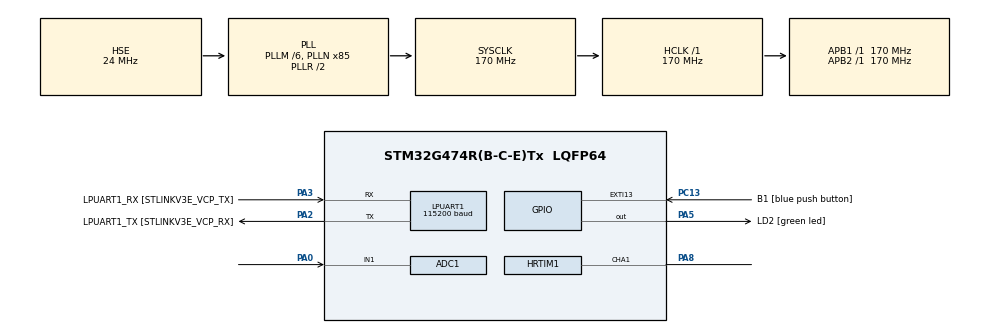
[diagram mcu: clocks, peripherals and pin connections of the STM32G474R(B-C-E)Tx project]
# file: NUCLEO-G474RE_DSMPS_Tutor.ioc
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ADC1.Channel-0\#ChannelRegularConversion=ADC_CHANNEL_1
ADC1.ClockPrescaler=ADC_CLOCK_SYNC_PCLK_DIV4
ADC1.EnableInjectedConversion=ENABLE
ADC1.ExternalTrigInjecConv=ADC_EXTERNALTRIGINJEC_HRTIM_TRG2
ADC1.InjNumberOfConversion=1
ADC1.InjectedChannel-1\#ChannelInjectedConversion=ADC_CHANNEL_1
ADC1.InjectedOffsetNumber-1\#ChannelInjectedConversion=ADC_OFFSET_NONE
ADC1.InjectedRank-1\#ChannelInjectedConversion=1
ADC1.InjectedSamplingTime-1\#ChannelInjectedConversion=ADC_SAMPLETIME_2CYCLES_5
ADC1.NbrOfConversionFlag=1
ADC1.OffsetNumber-0\#ChannelRegularConversion=ADC_OFFSET_NONE
ADC1.Rank-0\#ChannelRegularConversion=1
ADC1.Rank1_Channel=ADC_CHANNEL_1
ADC1.SamplingTime-0\#ChannelRegularConversion=ADC_SAMPLETIME_2CYCLES_5
ADC1.master=1
HRTIM1.ADCTrigger2_Source1=HRTIM_ADCTRIGGEREVENT24_TIMERA_PERIOD
HRTIM1.ADCTrigger_Id2=HRTIM_ADCTRIGGER_2
HRTIM1.CompareUnit1-Output_TA1=HRTIM_COMPAREUNIT_1
HRTIM1.CompareValue1-Output_TA1=54400/2
HRTIM1.NumberADCTriggerSource2=1
HRTIM1.NumberResetSource1-Output_TA1=1
HRTIM1.NumberSetSource1-Output_TA1=1
HRTIM1.NumberUpdateTrigger-Output_TA1=0
HRTIM1.Periode_TA=54400
HRTIM1.ResetOutput1_Source1-Output_TA1=HRTIM_OUTPUTRESET_TIMCMP1
HRTIM1.SetOutput1_Source1-Output_TA1=HRTIM_OUTPUTSET_TIMPER
LPUART1.BaudRate=115200
LPUART1.WordLength=UART_WORDLENGTH_8B
Mcu.Family=STM32G4
Mcu.Name=STM32G474R(B-C-E)Tx
Mcu.Package=LQFP64
NVIC.ADC1_2_IRQn=true\:0\:0\:false\:false\:true\:true\:true\:true
NVIC.EXTI15_10_IRQn=true\:0\:0\:false\:false\:true\:true\:true\:true
NVIC.PriorityGroup=NVIC_PRIORITYGROUP_4
PA0.Mode=IN1-Single-Ended
PA0.Signal=ADC1_IN1
PA13.GPIO_Label=T_SWDIO
PA13.Mode=Trace_Asynchronous_SW
PA13.Signal=SYS_JTMS-SWDIO
PA14.GPIO_Label=T_SWCLK
PA14.Mode=Trace_Asynchronous_SW
PA14.Signal=SYS_JTCK-SWCLK
PA2.GPIO_Label=LPUART1_TX [STLINKV3E_VCP_RX]
PA2.Mode=Asynchronous
PA2.Signal=LPUART1_TX
PA3.GPIO_Label=LPUART1_RX [STLINKV3E_VCP_TX]
PA3.Mode=Asynchronous
PA3.Signal=LPUART1_RX
PA5.GPIO_Label=LD2 [green led]
PA5.Signal=GPIO_Output
PA8.GPIO_Speed_High_Default=GPIO_SPEED_FREQ_LOW
PA8.Mode=Output_TA1
PA8.Signal=HRTIM1_CHA1
PB3.GPIO_Label=T_SWO
PB3.Mode=Trace_Asynchronous_SW
PB3.Signal=SYS_JTDO-SWO
PC13.GPIO_Label=B1 [blue push button]
PC13.Signal=GPXTI13
PC14-OSC32_IN.Mode=LSE-External-Oscillator
PC14-OSC32_IN.Signal=RCC_OSC32_IN
PC15-OSC32_OUT.Mode=LSE-External-Oscillator
PC15-OSC32_OUT.Signal=RCC_OSC32_OUT
PF0-OSC_IN.Mode=HSE-External-Oscillator
PF0-OSC_IN.Signal=RCC_OSC_IN
PF1-OSC_OUT.Mode=HSE-External-Oscillator
PF1-OSC_OUT.Signal=RCC_OSC_OUT
ProjectManager.HeapSize=0x200
ProjectManager.StackSize=0x400
ProjectManager.TargetToolchain=STM32CubeIDE
RCC.ADC12Freq_Value=170000000
RCC.ADC345Freq_Value=170000000
RCC.AHBFreq_Value=170000000
RCC.APB1Freq_Value=170000000
RCC.APB1TimFreq_Value=170000000
RCC.APB2Freq_Value=170000000
RCC.APB2TimFreq_Value=170000000
RCC.CortexFreq_Value=170000000
RCC.EXTERNAL_CLOCK_VALUE=12288000
RCC.HCLKFreq_Value=170000000
RCC.HSE_VALUE=24000000
RCC.HSI48_VALUE=48000000
RCC.HSI_VALUE=16000000
RCC.PLLM=RCC_PLLM_DIV6
RCC.PLLN=85
RCC.PLLSourceVirtual=RCC_PLLSOURCE_HSE
RCC.RTCClockSelection=RCC_RTCCLKSOURCE_LSE
RCC.SYSCLKFreq_VALUE=170000000
RCC.SYSCLKSource=RCC_SYSCLKSOURCE_PLLCLK
RCC.USBFreq_Value=170000000
RCC.VCOOutputFreq_Value=340000000
VP_SYS_VS_DBSignals.Mode=DisableDeadBatterySignals
board=NUCLEO-G474RE

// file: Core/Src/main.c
/* USER CODE BEGIN Header */
/**
  ******************************************************************************
  * @file           : main.c
  * @brief          : Main program body
  ******************************************************************************
  * @attention
  *
  * Copyright (c) 2023 STMicroelectronics.
  * All rights reserved.
  *
  * This software is licensed under terms that can be found in the LICENSE file
  * in the root directory of this software component.
  * If no LICENSE file comes with this software, it is provided AS-IS.
  *
  ******************************************************************************
  */
/* USER CODE END Header */
#include "main.h"

ADC_HandleTypeDef hadc1;

HRTIM_HandleTypeDef hhrtim1;

UART_HandleTypeDef hlpuart1;

/* USER CODE BEGIN PV */

uint16_t VoutMeasured;

/* USER CODE END PV */

void SystemClock_Config(void);
static void MX_GPIO_Init(void);
static void MX_LPUART1_UART_Init(void);
static void MX_ADC1_Init(void);
static void MX_HRTIM1_Init(void);

int main(void)
{

  /* MCU Configuration--------------------------------------------------------*/

  /* Reset of all peripherals, Initializes the Flash interface and the Systick. */
  HAL_Init();

  /* Configure the system clock */
  SystemClock_Config();

  /* Initialize all configured peripherals */
  MX_GPIO_Init();
  MX_LPUART1_UART_Init();
  MX_ADC1_Init();
  MX_HRTIM1_Init();
  /* USER CODE BEGIN 2 */

  HAL_HRTIM_WaveformOutputStart(&hhrtim1, HRTIM_OUTPUT_TA1);
  HAL_HRTIM_WaveformCounterStart(&hhrtim1, HRTIM_TIMERID_TIMER_A);

  /* Run the ADC calibration in single-ended mode */
  HAL_ADCEx_Calibration_Start(&hadc1, ADC_SINGLE_ENDED);

  /* Start ADC1 Injected Conversions with Interrupt*/
  HAL_ADCEx_InjectedStart_IT(&hadc1);

  /* USER CODE END 2 */

  /* Infinite loop */
  while (1)
  {

  }
}

void SystemClock_Config(void)
{
  RCC_OscInitTypeDef RCC_OscInitStruct = {0};
  RCC_ClkInitTypeDef RCC_ClkInitStruct = {0};

  /** Configure the main internal regulator output voltage
  */
  HAL_PWREx_ControlVoltageScaling(PWR_REGULATOR_VOLTAGE_SCALE1_BOOST);

  /** Initializes the RCC Oscillators according to the specified parameters
  * in the RCC_OscInitTypeDef structure.
  */
  RCC_OscInitStruct.OscillatorType = RCC_OSCILLATORTYPE_HSE;
  RCC_OscInitStruct.HSEState = RCC_HSE_ON;
  RCC_OscInitStruct.PLL.PLLState = RCC_PLL_ON;
  RCC_OscInitStruct.PLL.PLLSource = RCC_PLLSOURCE_HSE;
  RCC_OscInitStruct.PLL.PLLM = RCC_PLLM_DIV6;
  RCC_OscInitStruct.PLL.PLLN = 85;
  RCC_OscInitStruct.PLL.PLLP = RCC_PLLP_DIV2;
  RCC_OscInitStruct.PLL.PLLQ = RCC_PLLQ_DIV2;
  RCC_OscInitStruct.PLL.PLLR = RCC_PLLR_DIV2;
  if (HAL_RCC_OscConfig(&RCC_OscInitStruct) != HAL_OK)
  {
    Error_Handler();
  }

  /** Initializes the CPU, AHB and APB buses clocks
  */
  RCC_ClkInitStruct.ClockType = RCC_CLOCKTYPE_HCLK|RCC_CLOCKTYPE_SYSCLK
                              |RCC_CLOCKTYPE_PCLK1|RCC_CLOCKTYPE_PCLK2;
  RCC_ClkInitStruct.SYSCLKSource = RCC_SYSCLKSOURCE_PLLCLK;
  RCC_ClkInitStruct.AHBCLKDivider = RCC_SYSCLK_DIV1;
  RCC_ClkInitStruct.APB1CLKDivider = RCC_HCLK_DIV1;
  RCC_ClkInitStruct.APB2CLKDivider = RCC_HCLK_DIV1;

  if (HAL_RCC_ClockConfig(&RCC_ClkInitStruct, FLASH_LATENCY_4) != HAL_OK)
  {
    Error_Handler();
  }
}

static void MX_ADC1_Init(void)
{

  ADC_MultiModeTypeDef multimode = {0};
  ADC_ChannelConfTypeDef sConfig = {0};
  ADC_InjectionConfTypeDef sConfigInjected = {0};

  /** Common config
  */
  hadc1.Instance = ADC1;
  hadc1.Init.ClockPrescaler = ADC_CLOCK_SYNC_PCLK_DIV4;
  hadc1.Init.Resolution = ADC_RESOLUTION_12B;
  hadc1.Init.DataAlign = ADC_DATAALIGN_RIGHT;
  hadc1.Init.GainCompensation = 0;
  hadc1.Init.ScanConvMode = ADC_SCAN_DISABLE;
  hadc1.Init.EOCSelection = ADC_EOC_SINGLE_CONV;
  hadc1.Init.LowPowerAutoWait = DISABLE;
  hadc1.Init.ContinuousConvMode = DISABLE;
  hadc1.Init.NbrOfConversion = 1;
  hadc1.Init.DiscontinuousConvMode = DISABLE;
  hadc1.Init.ExternalTrigConv = ADC_SOFTWARE_START;
  hadc1.Init.ExternalTrigConvEdge = ADC_EXTERNALTRIGCONVEDGE_NONE;
  hadc1.Init.DMAContinuousRequests = DISABLE;
  hadc1.Init.Overrun = ADC_OVR_DATA_PRESERVED;
  hadc1.Init.OversamplingMode = DISABLE;
  if (HAL_ADC_Init(&hadc1) != HAL_OK)
  {
    Error_Handler();
  }

  /** Configure the ADC multi-mode
  */
  multimode.Mode = ADC_MODE_INDEPENDENT;
  if (HAL_ADCEx_MultiModeConfigChannel(&hadc1, &multimode) != HAL_OK)
  {
    Error_Handler();
  }

  /** Configure Regular Channel
  */
  sConfig.Channel = ADC_CHANNEL_1;
  sConfig.Rank = ADC_REGULAR_RANK_1;
  sConfig.SamplingTime = ADC_SAMPLETIME_2CYCLES_5;
  sConfig.SingleDiff = ADC_SINGLE_ENDED;
  sConfig.OffsetNumber = ADC_OFFSET_NONE;
  sConfig.Offset = 0;
  if (HAL_ADC_ConfigChannel(&hadc1, &sConfig) != HAL_OK)
  {
    Error_Handler();
  }

  /** Configure Injected Channel
  */
  sConfigInjected.InjectedChannel = ADC_CHANNEL_1;
  sConfigInjected.InjectedRank = ADC_INJECTED_RANK_1;
  sConfigInjected.InjectedSamplingTime = ADC_SAMPLETIME_2CYCLES_5;
  sConfigInjected.InjectedSingleDiff = ADC_SINGLE_ENDED;
  sConfigInjected.InjectedOffsetNumber = ADC_OFFSET_NONE;
  sConfigInjected.InjectedOffset = 0;
  sConfigInjected.InjectedNbrOfConversion = 1;
  sConfigInjected.InjectedDiscontinuousConvMode = DISABLE;
  sConfigInjected.AutoInjectedConv = DISABLE;
  sConfigInjected.QueueInjectedContext = DISABLE;
  sConfigInjected.ExternalTrigInjecConv = ADC_EXTERNALTRIGINJEC_HRTIM_TRG2;
  sConfigInjected.ExternalTrigInjecConvEdge = ADC_EXTERNALTRIGINJECCONV_EDGE_RISING;
  sConfigInjected.InjecOversamplingMode = DISABLE;
  if (HAL_ADCEx_InjectedConfigChannel(&hadc1, &sConfigInjected) != HAL_OK)
  {
    Error_Handler();
  }

}

static void MX_HRTIM1_Init(void)
{

  HRTIM_ADCTriggerCfgTypeDef pADCTriggerCfg = {0};
  HRTIM_TimeBaseCfgTypeDef pTimeBaseCfg = {0};
  HRTIM_TimerCtlTypeDef pTimerCtl = {0};
  HRTIM_TimerCfgTypeDef pTimerCfg = {0};
  HRTIM_CompareCfgTypeDef pCompareCfg = {0};
  HRTIM_OutputCfgTypeDef pOutputCfg = {0};

  hhrtim1.Instance = HRTIM1;
  hhrtim1.Init.HRTIMInterruptResquests = HRTIM_IT_NONE;
  hhrtim1.Init.SyncOptions = HRTIM_SYNCOPTION_NONE;
  if (HAL_HRTIM_Init(&hhrtim1) != HAL_OK)
  {
    Error_Handler();
  }
  if (HAL_HRTIM_DLLCalibrationStart(&hhrtim1, HRTIM_CALIBRATIONRATE_3) != HAL_OK)
  {
    Error_Handler();
  }
  if (HAL_HRTIM_PollForDLLCalibration(&hhrtim1, 10) != HAL_OK)
  {
    Error_Handler();
  }
  pADCTriggerCfg.UpdateSource = HRTIM_ADCTRIGGERUPDATE_TIMER_A;
  pADCTriggerCfg.Trigger = HRTIM_ADCTRIGGEREVENT24_TIMERA_PERIOD;
  if (HAL_HRTIM_ADCTriggerConfig(&hhrtim1, HRTIM_ADCTRIGGER_2, &pADCTriggerCfg) != HAL_OK)
  {
    Error_Handler();
  }
  if (HAL_HRTIM_ADCPostScalerConfig(&hhrtim1, HRTIM_ADCTRIGGER_2, 0x0) != HAL_OK)
  {
    Error_Handler();
  }
  pTimeBaseCfg.Period = 54400;
  pTimeBaseCfg.RepetitionCounter = 0x00;
  pTimeBaseCfg.PrescalerRatio = HRTIM_PRESCALERRATIO_MUL32;
  pTimeBaseCfg.Mode = HRTIM_MODE_CONTINUOUS;
  if (HAL_HRTIM_TimeBaseConfig(&hhrtim1, HRTIM_TIMERINDEX_TIMER_A, &pTimeBaseCfg) != HAL_OK)
  {
    Error_Handler();
  }
  pTimerCtl.UpDownMode = HRTIM_TIMERUPDOWNMODE_UP;
  pTimerCtl.GreaterCMP1 = HRTIM_TIMERGTCMP1_EQUAL;
  pTimerCtl.DualChannelDacEnable = HRTIM_TIMER_DCDE_DISABLED;
  if (HAL_HRTIM_WaveformTimerControl(&hhrtim1, HRTIM_TIMERINDEX_TIMER_A, &pTimerCtl) != HAL_OK)
  {
    Error_Handler();
  }
  pTimerCfg.InterruptRequests = HRTIM_TIM_IT_NONE;
  pTimerCfg.DMARequests = HRTIM_TIM_DMA_NONE;
  pTimerCfg.DMASrcAddress = 0x0000;
  pTimerCfg.DMADstAddress = 0x0000;
  pTimerCfg.DMASize = 0x1;
  pTimerCfg.HalfModeEnable = HRTIM_HALFMODE_DISABLED;
  pTimerCfg.InterleavedMode = HRTIM_INTERLEAVED_MODE_DISABLED;
  pTimerCfg.StartOnSync = HRTIM_SYNCSTART_DISABLED;
  pTimerCfg.ResetOnSync = HRTIM_SYNCRESET_DISABLED;
  pTimerCfg.DACSynchro = HRTIM_DACSYNC_NONE;
  pTimerCfg.PreloadEnable = HRTIM_PRELOAD_DISABLED;
  pTimerCfg.UpdateGating = HRTIM_UPDATEGATING_INDEPENDENT;
  pTimerCfg.BurstMode = HRTIM_TIMERBURSTMODE_MAINTAINCLOCK;
  pTimerCfg.RepetitionUpdate = HRTIM_UPDATEONREPETITION_DISABLED;
  pTimerCfg.PushPull = HRTIM_TIMPUSHPULLMODE_DISABLED;
  pTimerCfg.FaultEnable = HRTIM_TIMFAULTENABLE_NONE;
  pTimerCfg.FaultLock = HRTIM_TIMFAULTLOCK_READWRITE;
  pTimerCfg.DeadTimeInsertion = HRTIM_TIMDEADTIMEINSERTION_DISABLED;
  pTimerCfg.DelayedProtectionMode = HRTIM_TIMER_A_B_C_DELAYEDPROTECTION_DISABLED;
  pTimerCfg.UpdateTrigger = HRTIM_TIMUPDATETRIGGER_NONE;
  pTimerCfg.ResetTrigger = HRTIM_TIMRESETTRIGGER_NONE;
  pTimerCfg.ResetUpdate = HRTIM_TIMUPDATEONRESET_DISABLED;
  pTimerCfg.ReSyncUpdate = HRTIM_TIMERESYNC_UPDATE_UNCONDITIONAL;
  if (HAL_HRTIM_WaveformTimerConfig(&hhrtim1, HRTIM_TIMERINDEX_TIMER_A, &pTimerCfg) != HAL_OK)
  {
    Error_Handler();
  }
  pCompareCfg.CompareValue = 54400/2;
  if (HAL_HRTIM_WaveformCompareConfig(&hhrtim1, HRTIM_TIMERINDEX_TIMER_A, HRTIM_COMPAREUNIT_1, &pCompareCfg) != HAL_OK)
  {
    Error_Handler();
  }
  pOutputCfg.Polarity = HRTIM_OUTPUTPOLARITY_HIGH;
  pOutputCfg.SetSource = HRTIM_OUTPUTSET_TIMPER;
  pOutputCfg.ResetSource = HRTIM_OUTPUTRESET_TIMCMP1;
  pOutputCfg.IdleMode = HRTIM_OUTPUTIDLEMODE_NONE;
  pOutputCfg.IdleLevel = HRTIM_OUTPUTIDLELEVEL_INACTIVE;
  pOutputCfg.FaultLevel = HRTIM_OUTPUTFAULTLEVEL_NONE;
  pOutputCfg.ChopperModeEnable = HRTIM_OUTPUTCHOPPERMODE_DISABLED;
  pOutputCfg.BurstModeEntryDelayed = HRTIM_OUTPUTBURSTMODEENTRY_REGULAR;
  if (HAL_HRTIM_WaveformOutputConfig(&hhrtim1, HRTIM_TIMERINDEX_TIMER_A, HRTIM_OUTPUT_TA1, &pOutputCfg) != HAL_OK)
  {
    Error_Handler();
  }
  HAL_HRTIM_MspPostInit(&hhrtim1);

}

static void MX_LPUART1_UART_Init(void)
{

  hlpuart1.Instance = LPUART1;
  hlpuart1.Init.BaudRate = 115200;
  hlpuart1.Init.WordLength = UART_WORDLENGTH_8B;
  hlpuart1.Init.StopBits = UART_STOPBITS_1;
  hlpuart1.Init.Parity = UART_PARITY_NONE;
  hlpuart1.Init.Mode = UART_MODE_TX_RX;
  hlpuart1.Init.HwFlowCtl = UART_HWCONTROL_NONE;
  hlpuart1.Init.OneBitSampling = UART_ONE_BIT_SAMPLE_DISABLE;
  hlpuart1.Init.ClockPrescaler = UART_PRESCALER_DIV1;
  hlpuart1.AdvancedInit.AdvFeatureInit = UART_ADVFEATURE_NO_INIT;
  if (HAL_UART_Init(&hlpuart1) != HAL_OK)
  {
    Error_Handler();
  }
  if (HAL_UARTEx_SetTxFifoThreshold(&hlpuart1, UART_TXFIFO_THRESHOLD_1_8) != HAL_OK)
  {
    Error_Handler();
  }
  if (HAL_UARTEx_SetRxFifoThreshold(&hlpuart1, UART_RXFIFO_THRESHOLD_1_8) != HAL_OK)
  {
    Error_Handler();
  }
  if (HAL_UARTEx_DisableFifoMode(&hlpuart1) != HAL_OK)
  {
    Error_Handler();
  }

}

static void MX_GPIO_Init(void)
{
  GPIO_InitTypeDef GPIO_InitStruct = {0};

  /* GPIO Ports Clock Enable */
  __HAL_RCC_GPIOC_CLK_ENABLE();
  __HAL_RCC_GPIOF_CLK_ENABLE();
  __HAL_RCC_GPIOA_CLK_ENABLE();
  __HAL_RCC_GPIOB_CLK_ENABLE();

  /*Configure GPIO pin Output Level */
  HAL_GPIO_WritePin(LD2_GPIO_Port, LD2_Pin, GPIO_PIN_RESET);

  /*Configure GPIO pin : B1_Pin */
  GPIO_InitStruct.Pin = B1_Pin;
  GPIO_InitStruct.Mode = GPIO_MODE_IT_RISING;
  GPIO_InitStruct.Pull = GPIO_NOPULL;
  HAL_GPIO_Init(B1_GPIO_Port, &GPIO_InitStruct);

  /*Configure GPIO pin : LD2_Pin */
  GPIO_InitStruct.Pin = LD2_Pin;
  GPIO_InitStruct.Mode = GPIO_MODE_OUTPUT_PP;
  GPIO_InitStruct.Pull = GPIO_NOPULL;
  GPIO_InitStruct.Speed = GPIO_SPEED_FREQ_LOW;
  HAL_GPIO_Init(LD2_GPIO_Port, &GPIO_InitStruct);

  /* EXTI interrupt init*/
  HAL_NVIC_SetPriority(EXTI15_10_IRQn, 0, 0);
  HAL_NVIC_EnableIRQ(EXTI15_10_IRQn);

}

/* USER CODE BEGIN 4 */

void HAL_ADCEx_InjectedConvCpltCallback(ADC_HandleTypeDef* hadc)
{
  /* Prevent unused argument(s) compilation warning */
  UNUSED(hadc);

  /* NOTE : This function Should not be modified, when the callback is needed,
            the HAL_ADCEx_InjectedConvCpltCallback could be implemented in the user file
  */

  GPIOB->BSRR = (1 << 8); // Set

  VoutMeasured = HAL_ADCEx_InjectedGetValue(&hadc1, ADC_INJECTED_RANK_1);
//  Verror =  (uint16_t ) VoutMeasured - (uint16_t) VoutTarget;

//	seterr = (-Kp * Verror) / 200;
//	Int_term_Buck = Int_term_Buck + ((-Ki * Verror) / 200);
//	pid_out = seterr + Int_term_Buck;
//
//	if (pid_out > 4800)
//		pid_out = 45000;
//	if (pid_out < 100)
//		pid_out = 100;

//	errorProp = (Kp * Verror) >> 5;
//	errorIntgr = errorIntgr + ((Ki * Verror) >> 4);
//	errorDiff = Verror >> Kd;
//
//	pid_out =   errorProp + errorIntgr + errorDiff;
//
//  __HAL_HRTIM_SETCOMPARE(&hhrtim1, HRTIM_TIMERINDEX_TIMER_E, HRTIM_COMPAREUNIT_3, pid_out);
//
  GPIOB->BSRR = (1 << 24); // Reset

}

/* USER CODE END 4 */

void Error_Handler(void)
{
  __disable_irq();
  while (1)
  {
  }
}
